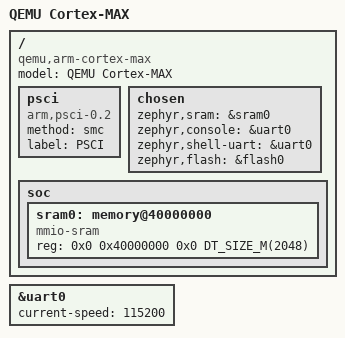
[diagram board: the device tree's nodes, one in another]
/*
 * Copyright (c) 2019 Carlo Caione <ccaione@baylibre.com>
 *
 * SPDX-License-Identifier: Apache-2.0
 *
 */

/dts-v1/;
#include <arm64/qemu-virt/qemu-virt-max.dtsi>

/ {
	model = "QEMU Cortex-MAX";
	compatible = "qemu,arm-cortex-max";

	psci {
		compatible = "arm,psci-0.2";
		method = "smc";
		label = "PSCI";
	};

	chosen {
		zephyr,sram = &sram0;
		zephyr,console = &uart0;
		zephyr,shell-uart = &uart0;
		zephyr,flash = &flash0;
	};

	soc {
		sram0: memory@40000000 {
			compatible = "mmio-sram";
			reg = <0x0 0x40000000 0x0 DT_SIZE_M(2048)>;
		};
	};

};

&uart0 {
	status = "okay";
	current-speed = <115200>;
};
